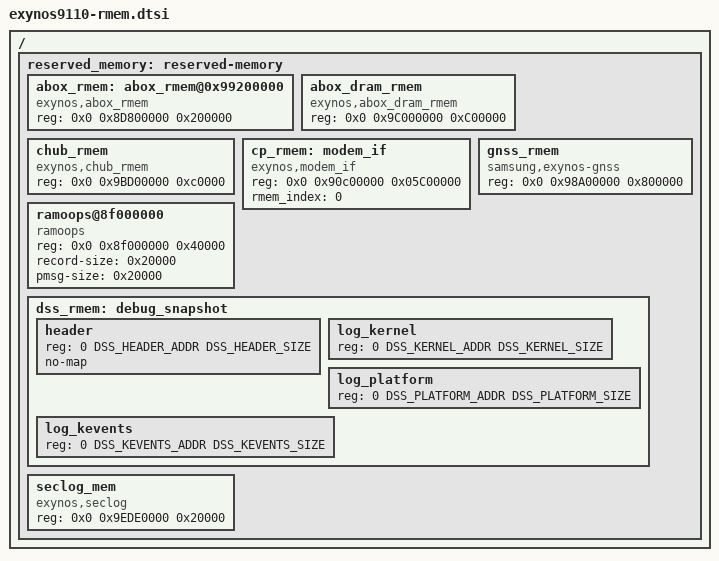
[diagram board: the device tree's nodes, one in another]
/*
 * SAMSUNG EXYNOS device tree source for reserved-memory
 *
 * Copyright (c) 2018 Samsung Electronics Co., Ltd.
 *		http://www.samsung.com
 *
 * This program is free software; you can redistribute it and/or modify
 * it under the terms of the GNU General Public License version 2 as
 * published by the Free Software Foundation.
 */

#include <dt-bindings/soc/samsung/debug-snapshot-def.h>

/ {
	reserved_memory: reserved-memory {
		#address-cells = <2>;
		#size-cells = <1>;
		ranges;

		abox_rmem: abox_rmem@0x99200000 {
			compatible = "exynos,abox_rmem";
			reg = <0x0 0x8D800000 0x200000>;
		};

		abox_dram_rmem: abox_dram_rmem {
			compatible = "exynos,abox_dram_rmem";
			reg = <0x0 0x9C000000 0xC00000>;
		};

                chub_rmem: chub_rmem {
                              compatible = "exynos,chub_rmem";
                              /* To dump SHUB SRAM out upon shub firmware crash */
                              reg = <0x0 0x9BD00000 0xc0000>;
                };

		/* TODO(b/179395386): rename modem_if back to cp_rmem after fixing bootloader to check compatible */
		cp_rmem: modem_if {
			compatible = "exynos,modem_if";
			reg = <0x0 0x90c00000 0x05C00000>;
			rmem_index = <0>;
		};

		gnss_rmem: gnss_rmem {
			compatible = "samsung,exynos-gnss";
			reg = <0x0 0x98A00000 0x800000>;
		};

		ramoops@8f000000 {
			compatible = "ramoops";
			reg = <0x0 0x8f000000 0x40000>;
			record-size = <0x20000>;
			pmsg-size = <0x20000>;
		};

                dss_rmem: debug_snapshot {
                        #address-cells = <2>;
                        #size-cells = <1>;
                        header: header {
                                reg = <0 DSS_HEADER_ADDR DSS_HEADER_SIZE>;
				no-map;
                        };
                        log_kernel: log_kernel {
                                reg = <0 DSS_KERNEL_ADDR DSS_KERNEL_SIZE>;
                        };
			log_platform: log_platform {
				reg = <0 DSS_PLATFORM_ADDR DSS_PLATFORM_SIZE>;
			};
			log_kevents: log_kevents {
				reg = <0 DSS_KEVENTS_ADDR DSS_KEVENTS_SIZE>;
			};
                };

		seclog_mem {
			compatible = "exynos,seclog";
			reg = <0x0 0x9EDE0000 0x20000>;
		};
	};
};
